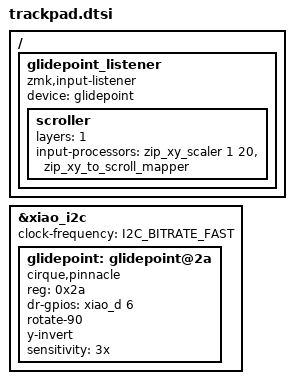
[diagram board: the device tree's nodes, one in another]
#include <behaviors/input_processor_gestures.dtsi>
#include <behaviors/input_processor_absolute_to_relative.dtsi>

&xiao_i2c {
    status="okay";
    clock-frequency = <I2C_BITRATE_FAST>;

    glidepoint: glidepoint@2a {
        compatible = "cirque,pinnacle";
        status = "okay";
        reg = <0x2a>;
        dr-gpios = <&xiao_d 6 (GPIO_ACTIVE_HIGH)>;
        rotate-90;
        y-invert;
        sensitivity = "3x";
    };
};

// &zip_gestures {
//     inertial-cursor;
// };

/ {
    glidepoint_listener: glidepoint_listener {
        compatible = "zmk,input-listener";
        status = "okay";
        device = <&glidepoint>;
        scroller {
            layers = <1>;
            input-processors = <
                &zip_xy_scaler 1 20
                &zip_xy_to_scroll_mapper
            >;
        };
    };
};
